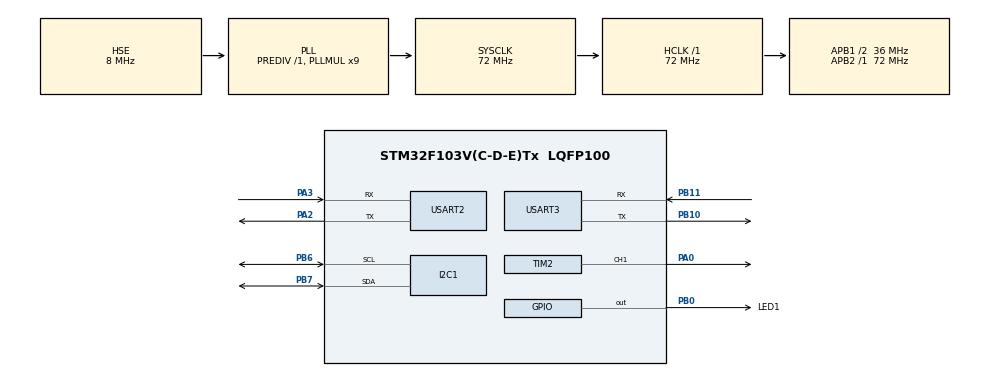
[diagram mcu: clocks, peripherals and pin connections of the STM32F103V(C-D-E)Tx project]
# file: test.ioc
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ADC1.Channel-0\#ChannelRegularConversion=ADC_CHANNEL_TEMPSENSOR
ADC1.ContinuousConvMode=ENABLE
ADC1.NbrOfConversionFlag=1
ADC1.Rank-0\#ChannelRegularConversion=1
ADC1.SamplingTime-0\#ChannelRegularConversion=ADC_SAMPLETIME_71CYCLES_5
ADC1.master=1
Dma.Request0=USART2_RX
Dma.Request1=USART2_TX
Dma.USART2_RX.0.Direction=DMA_PERIPH_TO_MEMORY
Dma.USART2_RX.0.Instance=DMA1_Channel6
Dma.USART2_RX.0.MemDataAlignment=DMA_MDATAALIGN_BYTE
Dma.USART2_RX.0.MemInc=DMA_MINC_ENABLE
Dma.USART2_RX.0.Mode=DMA_NORMAL
Dma.USART2_RX.0.PeriphDataAlignment=DMA_PDATAALIGN_BYTE
Dma.USART2_RX.0.PeriphInc=DMA_PINC_DISABLE
Dma.USART2_RX.0.Priority=DMA_PRIORITY_LOW
Dma.USART2_TX.1.Direction=DMA_MEMORY_TO_PERIPH
Dma.USART2_TX.1.Instance=DMA1_Channel7
Dma.USART2_TX.1.MemDataAlignment=DMA_MDATAALIGN_BYTE
Dma.USART2_TX.1.MemInc=DMA_MINC_ENABLE
Dma.USART2_TX.1.Mode=DMA_NORMAL
Dma.USART2_TX.1.PeriphDataAlignment=DMA_PDATAALIGN_BYTE
Dma.USART2_TX.1.PeriphInc=DMA_PINC_DISABLE
Dma.USART2_TX.1.Priority=DMA_PRIORITY_LOW
Mcu.Family=STM32F1
Mcu.Name=STM32F103V(C-D-E)Tx
Mcu.Package=LQFP100
NVIC.DMA1_Channel6_IRQn=true\:1\:0\:true\:false\:true\:false\:true
NVIC.DMA1_Channel7_IRQn=true\:1\:0\:true\:false\:true\:false\:true
NVIC.PriorityGroup=NVIC_PRIORITYGROUP_4
NVIC.USART2_IRQn=true\:1\:0\:true\:false\:true\:true\:true
OSC_IN.Mode=HSE-External-Oscillator
OSC_IN.Signal=RCC_OSC_IN
OSC_OUT.Mode=HSE-External-Oscillator
OSC_OUT.Signal=RCC_OSC_OUT
PA0-WKUP.Signal=S_TIM2_CH1_ETR
PA13.Mode=Serial_Wire
PA13.Signal=SYS_JTMS-SWDIO
PA14.Mode=Serial_Wire
PA14.Signal=SYS_JTCK-SWCLK
PA2.Mode=Asynchronous
PA2.Signal=USART2_TX
PA3.GPIO_PuPd=GPIO_PULLUP
PA3.Mode=Asynchronous
PA3.Signal=USART2_RX
PB0.GPIO_Label=LED1
PB0.Signal=GPIO_Output
PB10.Mode=Asynchronous
PB10.Signal=USART3_TX
PB11.Mode=Asynchronous
PB11.Signal=USART3_RX
PB6.Mode=I2C
PB6.Signal=I2C1_SCL
PB7.Mode=I2C
PB7.Signal=I2C1_SDA
PC14-OSC32_IN.Mode=LSE-External-Oscillator
PC14-OSC32_IN.Signal=RCC_OSC32_IN
PC15-OSC32_OUT.Mode=LSE-External-Oscillator
PC15-OSC32_OUT.Signal=RCC_OSC32_OUT
ProjectManager.HeapSize=0x200
ProjectManager.StackSize=0x400
ProjectManager.TargetToolchain=MDK-ARM V5
RCC.ADCPresc=RCC_ADCPCLK2_DIV6
RCC.AHBFreq_Value=72000000
RCC.APB1CLKDivider=RCC_HCLK_DIV2
RCC.APB1Freq_Value=36000000
RCC.APB1TimFreq_Value=72000000
RCC.APB2Freq_Value=72000000
RCC.APB2TimFreq_Value=72000000
RCC.HCLKFreq_Value=72000000
RCC.PLLMUL=RCC_PLL_MUL9
RCC.PLLSourceVirtual=RCC_PLLSOURCE_HSE
RCC.SYSCLKFreq_VALUE=72000000
RCC.SYSCLKSource=RCC_SYSCLKSOURCE_PLLCLK
RCC.USBFreq_Value=72000000
SH.S_TIM2_CH1_ETR.0=TIM2_CH1,PWM Generation1 CH1
TIM2.Channel-PWM\ Generation1\ CH1=TIM_CHANNEL_1
TIM2.Period=20000
TIM2.Prescaler=71
USART2.VirtualMode=VM_ASYNC
USART3.VirtualMode=VM_ASYNC
VP_ADC1_TempSens_Input.Mode=IN-TempSens
VP_TIM2_VS_ClockSourceINT.Mode=Internal
board=custom

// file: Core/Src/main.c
/* USER CODE BEGIN Header */
/**
  ******************************************************************************
  * @file           : main.c
  * @brief          : Main program body
  ******************************************************************************
  * @attention
  *
  * Copyright (c) 2022 STMicroelectronics.
  * All rights reserved.
  *
  * This software is licensed under terms that can be found in the LICENSE file
  * in the root directory of this software component.
  * If no LICENSE file comes with this software, it is provided AS-IS.
  *
  ******************************************************************************
  */
/* USER CODE END Header */
#include "main.h"
#include "adc.h"
#include "dma.h"
#include "i2c.h"
#include "tim.h"
#include "usart.h"
#include "gpio.h"

/* USER CODE BEGIN Includes */
#include <stdio.h>
#include <string.h>
#include "sht30_i2c_driver.h"
/* USER CODE END Includes */

/* USER CODE BEGIN PV */
extern uint8_t I2CRXBuffer[6];
/* USER CODE END PV */

void SystemClock_Config(void);

int main(void)
{
  /* USER CODE BEGIN 1 */
  int i;
  /* USER CODE END 1 */

  /* MCU Configuration--------------------------------------------------------*/

  /* Reset of all peripherals, Initializes the Flash interface and the Systick. */
  HAL_Init();

  /* USER CODE BEGIN Init */
  memset(I2CRXBuffer,0,sizeof(I2CRXBuffer));
  /* USER CODE END Init */

  /* Configure the system clock */
  SystemClock_Config();

  /* Initialize all configured peripherals */
  MX_GPIO_Init();
  MX_USART2_UART_Init();
  MX_DMA_Init();
  MX_ADC1_Init();
  MX_TIM2_Init();
  MX_USART3_UART_Init();
  MX_I2C1_Init();

  /* Infinite loop */
  /* USER CODE BEGIN WHILE */
  while (1)
  {

    HAL_GPIO_WritePin(GPIOB,LED1_Pin,GPIO_PIN_SET);
    HAL_Delay(2000);
    for (i=0;i<20;i++)
    {
    HAL_GPIO_TogglePin(GPIOB,LED1_Pin);
    HAL_Delay(50);
    }
    Measure_TR();

    /* USER CODE END WHILE */

  }
}

void SystemClock_Config(void)
{
  RCC_OscInitTypeDef RCC_OscInitStruct = {0};
  RCC_ClkInitTypeDef RCC_ClkInitStruct = {0};
  RCC_PeriphCLKInitTypeDef PeriphClkInit = {0};

  /** Initializes the RCC Oscillators according to the specified parameters
  * in the RCC_OscInitTypeDef structure.
  */
  RCC_OscInitStruct.OscillatorType = RCC_OSCILLATORTYPE_HSE;
  RCC_OscInitStruct.HSEState = RCC_HSE_ON;
  RCC_OscInitStruct.HSEPredivValue = RCC_HSE_PREDIV_DIV1;
  RCC_OscInitStruct.HSIState = RCC_HSI_ON;
  RCC_OscInitStruct.PLL.PLLState = RCC_PLL_ON;
  RCC_OscInitStruct.PLL.PLLSource = RCC_PLLSOURCE_HSE;
  RCC_OscInitStruct.PLL.PLLMUL = RCC_PLL_MUL9;
  if (HAL_RCC_OscConfig(&RCC_OscInitStruct) != HAL_OK)
  {
    Error_Handler();
  }
  /** Initializes the CPU, AHB and APB buses clocks
  */
  RCC_ClkInitStruct.ClockType = RCC_CLOCKTYPE_HCLK|RCC_CLOCKTYPE_SYSCLK
                              |RCC_CLOCKTYPE_PCLK1|RCC_CLOCKTYPE_PCLK2;
  RCC_ClkInitStruct.SYSCLKSource = RCC_SYSCLKSOURCE_PLLCLK;
  RCC_ClkInitStruct.AHBCLKDivider = RCC_SYSCLK_DIV1;
  RCC_ClkInitStruct.APB1CLKDivider = RCC_HCLK_DIV2;
  RCC_ClkInitStruct.APB2CLKDivider = RCC_HCLK_DIV1;

  if (HAL_RCC_ClockConfig(&RCC_ClkInitStruct, FLASH_LATENCY_2) != HAL_OK)
  {
    Error_Handler();
  }
  PeriphClkInit.PeriphClockSelection = RCC_PERIPHCLK_ADC;
  PeriphClkInit.AdcClockSelection = RCC_ADCPCLK2_DIV6;
  if (HAL_RCCEx_PeriphCLKConfig(&PeriphClkInit) != HAL_OK)
  {
    Error_Handler();
  }
}

void Error_Handler(void)
{
  __disable_irq();
  while (1)
  {
  }
}
